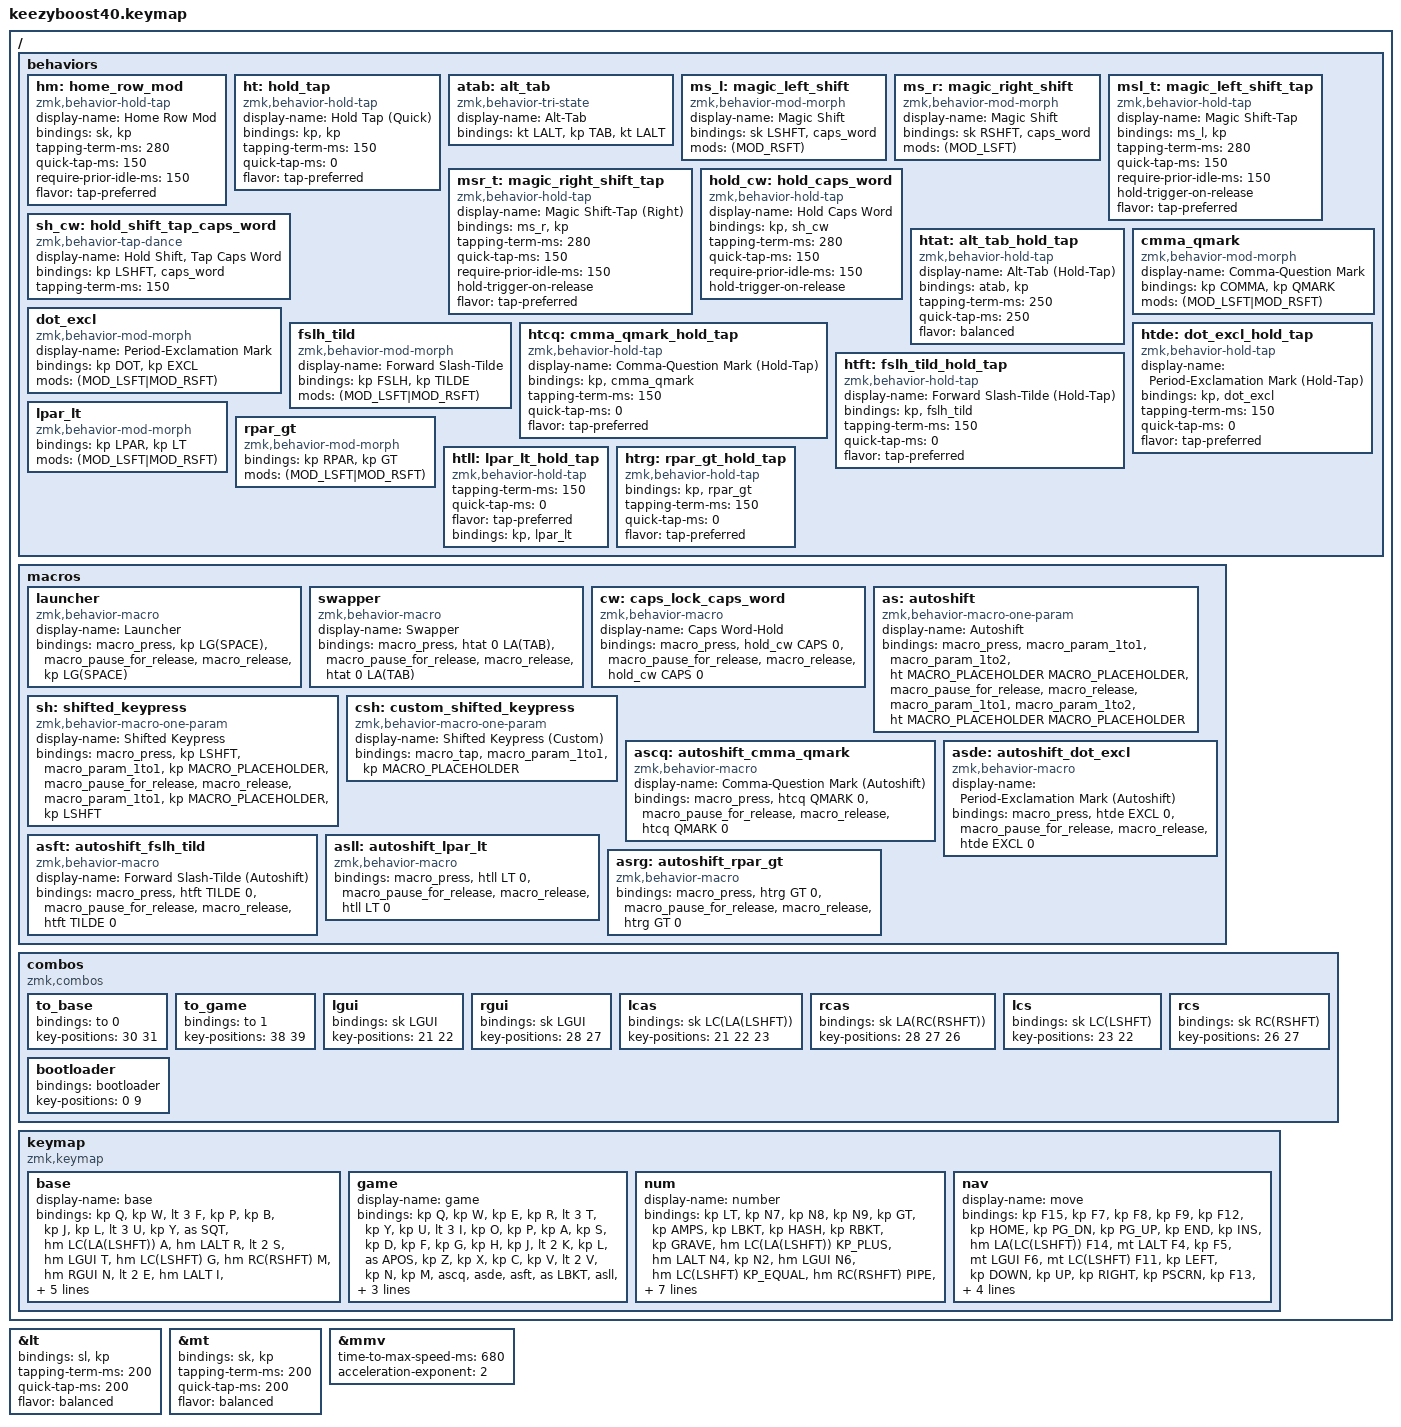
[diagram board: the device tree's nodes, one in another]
// dt-formatter: multilineListCommaStyle="leading"

#include <behaviors/none.dtsi>
#include <behaviors/transparent.dtsi>
#include <dt-bindings/zmk/mouse.h>
#include <behaviors.dtsi>
#include <dt-bindings/zmk/keys.h>

&lt {
    bindings = <&sl>, <&kp>;

    tapping-term-ms = <200>;
    quick-tap-ms = <200>;
    flavor = "balanced";
};

&mt {
    bindings = <&sk>, <&kp>;

    tapping-term-ms = <200>;
    quick-tap-ms = <200>;
    flavor = "balanced";
};

&mmv {
    time-to-max-speed-ms = <680>;
    acceleration-exponent = <2>;
};

/ {
    behaviors {
        hm: home_row_mod {
            display-name = "Home Row Mod";
            compatible = "zmk,behavior-hold-tap";
            #binding-cells = <2>;
            bindings = <&sk>, <&kp>;

            tapping-term-ms = <280>;
            quick-tap-ms = <150>;
            require-prior-idle-ms = <150>;
            flavor = "tap-preferred";
        };

        // Quick hold tap, i.e. for auto-shift

        ht: hold_tap {
            display-name = "Hold Tap (Quick)";
            compatible = "zmk,behavior-hold-tap";
            #binding-cells = <2>;
            bindings = <&kp>, <&kp>;

            tapping-term-ms = <150>;
            quick-tap-ms = <0>;
            flavor = "tap-preferred";
        };

        atab: alt_tab {
            display-name = "Alt-Tab";
            compatible = "zmk,behavior-tri-state";
            #binding-cells = <0>;
            bindings = <&kt LALT>, <&kp TAB>, <&kt LALT>;
        };

        // Unmodded: Left Shift | With Shift: Caps Word.

        ms_l: magic_left_shift {
            display-name = "Magic Shift";
            compatible = "zmk,behavior-mod-morph";
            #binding-cells = <0>;
            bindings = <&sk LSHFT>, <&caps_word>;

            mods = <(MOD_RSFT)>;
        };

        // Unmodded: Right Shift | With Shift: Caps Word.

        ms_r: magic_right_shift {
            display-name = "Magic Shift";
            compatible = "zmk,behavior-mod-morph";
            #binding-cells = <0>;
            bindings = <&sk RSHFT>, <&caps_word>;

            mods = <(MOD_LSFT)>;
        };

        // Hold: &ms_l | Tap: &kp

        msl_t: magic_left_shift_tap {
            display-name = "Magic Shift-Tap";
            compatible = "zmk,behavior-hold-tap";
            #binding-cells = <2>;
            bindings = <&ms_l>, <&kp>;

            tapping-term-ms = <280>;
            quick-tap-ms = <150>;
            require-prior-idle-ms = <150>;
            hold-trigger-on-release;
            flavor = "tap-preferred";
        };

        // Hold: &ms_r | Tap: &kp

        msr_t: magic_right_shift_tap {
            display-name = "Magic Shift-Tap (Right)";
            compatible = "zmk,behavior-hold-tap";
            #binding-cells = <2>;
            bindings = <&ms_r>, <&kp>;

            tapping-term-ms = <280>;
            quick-tap-ms = <150>;
            require-prior-idle-ms = <150>;
            hold-trigger-on-release;
            flavor = "tap-preferred";
        };

        hold_cw: hold_caps_word {
            display-name = "Hold Caps Word";
            compatible = "zmk,behavior-hold-tap";
            #binding-cells = <2>;
            bindings = <&kp>, <&sh_cw>;

            tapping-term-ms = <280>;
            quick-tap-ms = <150>;
            require-prior-idle-ms = <150>;
            hold-trigger-on-release;
        };

        sh_cw: hold_shift_tap_caps_word {
            display-name = "Hold Shift, Tap Caps Word";
            compatible = "zmk,behavior-tap-dance";
            #binding-cells = <0>;
            bindings = <&kp LSHFT>, <&caps_word>;

            tapping-term-ms = <150>;
        };

        htat: alt_tab_hold_tap {
            display-name = "Alt-Tab (Hold-Tap)";
            compatible = "zmk,behavior-hold-tap";
            #binding-cells = <2>;
            bindings = <&atab>, <&kp>;

            tapping-term-ms = <250>;
            quick-tap-ms = <250>;
            flavor = "balanced";
        };

        cmma_qmark: cmma_qmark {
            display-name = "Comma-Question Mark";
            compatible = "zmk,behavior-mod-morph";
            #binding-cells = <0>;
            bindings = <&kp COMMA>, <&kp QMARK>;

            mods = <(MOD_LSFT|MOD_RSFT)>;
        };

        dot_excl: dot_excl {
            display-name = "Period-Exclamation Mark";
            compatible = "zmk,behavior-mod-morph";
            #binding-cells = <0>;
            bindings = <&kp DOT>, <&kp EXCL>;

            mods = <(MOD_LSFT|MOD_RSFT)>;
        };

        fslh_tild: fslh_tild {
            display-name = "Forward Slash-Tilde";
            compatible = "zmk,behavior-mod-morph";
            #binding-cells = <0>;
            bindings = <&kp FSLH>, <&kp TILDE>;

            mods = <(MOD_LSFT|MOD_RSFT)>;
        };

        htcq: cmma_qmark_hold_tap {
            display-name = "Comma-Question Mark (Hold-Tap)";
            compatible = "zmk,behavior-hold-tap";
            #binding-cells = <2>;
            bindings = <&kp>, <&cmma_qmark>;

            tapping-term-ms = <150>;
            quick-tap-ms = <0>;
            flavor = "tap-preferred";
        };

        htde: dot_excl_hold_tap {
            display-name = "Period-Exclamation Mark (Hold-Tap)";
            compatible = "zmk,behavior-hold-tap";
            #binding-cells = <2>;
            bindings = <&kp>, <&dot_excl>;

            tapping-term-ms = <150>;
            quick-tap-ms = <0>;
            flavor = "tap-preferred";
        };

        htft: fslh_tild_hold_tap {
            display-name = "Forward Slash-Tilde (Hold-Tap)";
            compatible = "zmk,behavior-hold-tap";
            #binding-cells = <2>;
            bindings = <&kp>, <&fslh_tild>;

            tapping-term-ms = <150>;
            quick-tap-ms = <0>;
            flavor = "tap-preferred";
        };

        lpar_lt: lpar_lt {
            compatible = "zmk,behavior-mod-morph";
            bindings = <&kp LPAR>, <&kp LT>;

            #binding-cells = <0>;
            mods = <(MOD_LSFT|MOD_RSFT)>;
        };

        rpar_gt: rpar_gt {
            compatible = "zmk,behavior-mod-morph";
            bindings = <&kp RPAR>, <&kp GT>;

            #binding-cells = <0>;
            mods = <(MOD_LSFT|MOD_RSFT)>;
        };

        htll: lpar_lt_hold_tap {
            compatible = "zmk,behavior-hold-tap";
            #binding-cells = <2>;
            tapping-term-ms = <150>;
            quick-tap-ms = <0>;
            flavor = "tap-preferred";
            bindings = <&kp>, <&lpar_lt>;
        };

        htrg: rpar_gt_hold_tap {
            compatible = "zmk,behavior-hold-tap";
            bindings = <&kp>, <&rpar_gt>;

            #binding-cells = <2>;
            tapping-term-ms = <150>;
            quick-tap-ms = <0>;
            flavor = "tap-preferred";
        };
    };

    macros {
        launcher: launcher {
            display-name = "Launcher";
            compatible = "zmk,behavior-macro";
            #binding-cells = <0>;
            bindings
                = <&macro_press>
                , <&kp LG(SPACE)>
                , <&macro_pause_for_release>
                , <&macro_release>
                , <&kp LG(SPACE)>
                ;
        };

        swapper: swapper {
            display-name = "Swapper";
            compatible = "zmk,behavior-macro";
            #binding-cells = <0>;
            bindings
                = <&macro_press>
                , <&htat 0 LA(TAB)>
                , <&macro_pause_for_release>
                , <&macro_release>
                , <&htat 0 LA(TAB)>
                ;
        };

        /**
         * Swap windows
         * Windows/Linux: Grave-Tab
         * MacOS: Ctrl-Tab (Cmd-Tab if CMD_SWAP)
         */
        /**
         * Swap applications
         * Windows/Linux: Alt-Tab
         * MacOS: Cmd-Tab
         */
        // Hold: Caps Lock; Tap: Caps Word

        cw: caps_lock_caps_word {
            display-name = "Caps Word-Hold";
            compatible = "zmk,behavior-macro";
            #binding-cells = <0>;
            bindings
                = <&macro_press>
                , <&hold_cw CAPS 0>
                , <&macro_pause_for_release>
                , <&macro_release>
                , <&hold_cw CAPS 0>
                ;
        };

        as: autoshift {
            display-name = "Autoshift";
            compatible = "zmk,behavior-macro-one-param";
            #binding-cells = <1>;
            bindings
                = <&macro_press>
                , <&macro_param_1to1 &macro_param_1to2 &ht MACRO_PLACEHOLDER MACRO_PLACEHOLDER>
                , <&macro_pause_for_release>
                , <&macro_release>
                , <&macro_param_1to1 &macro_param_1to2 &ht MACRO_PLACEHOLDER MACRO_PLACEHOLDER>
                ;
        };

        sh: shifted_keypress {
            display-name = "Shifted Keypress";
            compatible = "zmk,behavior-macro-one-param";
            #binding-cells = <1>;
            bindings
                = <&macro_press>
                , <&kp LSHFT &macro_param_1to1 &kp MACRO_PLACEHOLDER>
                , <&macro_pause_for_release>
                , <&macro_release>
                , <&macro_param_1to1 &kp MACRO_PLACEHOLDER &kp LSHFT>
                ;
        };

        csh: custom_shifted_keypress {
            display-name = "Shifted Keypress (Custom)";
            compatible = "zmk,behavior-macro-one-param";
            #binding-cells = <1>;
            bindings = <&macro_tap>, <&macro_param_1to1 &kp MACRO_PLACEHOLDER>;
        };

        ascq: autoshift_cmma_qmark {
            display-name = "Comma-Question Mark (Autoshift)";
            compatible = "zmk,behavior-macro";
            #binding-cells = <0>;
            bindings
                = <&macro_press>
                , <&htcq QMARK 0>
                , <&macro_pause_for_release>
                , <&macro_release>
                , <&htcq QMARK 0>
                ;
        };

        asde: autoshift_dot_excl {
            display-name = "Period-Exclamation Mark (Autoshift)";
            compatible = "zmk,behavior-macro";
            #binding-cells = <0>;
            bindings
                = <&macro_press>
                , <&htde EXCL 0>
                , <&macro_pause_for_release>
                , <&macro_release>
                , <&htde EXCL 0>
                ;
        };

        asft: autoshift_fslh_tild {
            display-name = "Forward Slash-Tilde (Autoshift)";
            compatible = "zmk,behavior-macro";
            #binding-cells = <0>;
            bindings
                = <&macro_press>
                , <&htft TILDE 0>
                , <&macro_pause_for_release>
                , <&macro_release>
                , <&htft TILDE 0>
                ;
        };

        asll: autoshift_lpar_lt {
            compatible = "zmk,behavior-macro";
            #binding-cells = <0>;
            bindings
                = <&macro_press>
                , <&htll LT 0>
                , <&macro_pause_for_release>
                , <&macro_release>
                , <&htll LT 0>
                ;
        };

        asrg: autoshift_rpar_gt {
            compatible = "zmk,behavior-macro";
            #binding-cells = <0>;
            bindings
                = <&macro_press>
                , <&htrg GT 0>
                , <&macro_pause_for_release>
                , <&macro_release>
                , <&htrg GT 0>
                ;
        };
    };

    combos {
        compatible = "zmk,combos";

        to_base {
            bindings = <&to 0>;
            key-positions = <30 31>; // QWF
        };

        to_game {
            bindings = <&to 1>;
            key-positions = <38 39>; // WFP
        };

        lgui {
            bindings = <&sk LGUI>;
            key-positions = <21 22>; // RST
        };

        rgui {
            bindings = <&sk LGUI>;
            key-positions = <28 27>;  // NEI
        };

        lcas {
            bindings = <&sk LC(LA(LSHFT))>;
            key-positions = <21 22 23>;
        };

        rcas {
            bindings = <&sk LA(RC(RSHFT))>;
            key-positions = <28 27 26>;
        };

        lcs {
            bindings = <&sk LC(LSHFT)>;
            key-positions = <23 22>;
        };

        rcs {
            bindings = <&sk RC(RSHFT)>;
            key-positions = <26 27>;
        };

        bootloader {
            bindings = <&bootloader>;
            key-positions = <0 9>;
        };
    };

    keymap {
        compatible = "zmk,keymap";

        base {
            display-name = "base";

            // ┏━━━━━━━┳━━━━━━━┳━━━━━━━┳━━━━━━━┳━━━━━━━┳━━━━━━━┳━━━━━━━┳━━━━━━━┳━━━━━━━┳━━━━━━━┓
            // ┃   Q   ┃   W   ┃   F   ┃   P   ┃   B   ┃   J   ┃   L   ┃   U   ┃   Y   ┃   '   ┃
            // ┃       ┃       ┃ (nav) ┃       ┃       ┃       ┃       ┃ (nav) ┃       ┃       ┃
            // ┣━━━━━━━╋━━━━━━━╋━━━━━━━╋━━━━━━━╋━━━━━━━┫━━━━━━━╋━━━━━━━╋━━━━━━━╋━━━━━━━╋━━━━━━━┫
            // ┃   A   ┃   R   ┃   S   ┃   T   ┃   G   ┃   M   ┃   N   ┃   E   ┃   I   ┃   O   ┃
            // ┃ (^-⇧) ┃ (ALT) ┃ (num) ┃ (GUI) ┃       ┃       ┃ (GUI) ┃ (num) ┃ (ALT) ┃ (^-⇧) ┃
            // ┣━━━━━━━╋━━━━━━━╋━━━━━━━╋━━━━━━━╋━━━━━━━┫━━━━━━━╋━━━━━━━╋━━━━━━━╋━━━━━━━╋━━━━━━━┫
            // ┃   Z   ┃   X   ┃   C   ┃   D   ┃   V   ┃   K   ┃   H   ┃   ,   ┃   .   ┃   /   ┃
            // ╋━━━━━━━╋━━━━━━━╋━━━━━━━╋━━━━━━━╋━━━━━━━╋━━━━━━━╋━━━━━━━╋━━━━━━━╋━━━━━━━╋━━━━━━━┫
            // ┃       ┃       ┃  ESC  ┃ SPACE ┃  TAB  ┃ ENTER ┃ BSPC  ┃  DEL  ┃       ┃       ┃
            // ┃       ┃       ┃       ┃ (CTL) ┃ (SFT) ┃ (SFT) ┃ (CTL) ┃       ┃       ┃       ┃
            // ┗━━━━━━━┻━━━━━━━┻━━━━━━━┻━━━━━━━┻━━━━━━━┻━━━━━━━┻━━━━━━━┻━━━━━━━┻━━━━━━━┻━━━━━━━┛

            bindings = <
&kp Q  &kp W  &lt 3 F  &kp P  &kp B  &kp J  &kp L  &lt 3 U  &kp Y  &as SQT  &hm LC(LA(LSHFT)) A  &hm LALT R  &lt 2 S  &hm LGUI T  &hm LC(LSHFT) G  &hm RC(RSHFT) M  &hm RGUI N  &lt 2 E  &hm LALT I  &hm LA(RC(RSHFT)) O  &kp Z  &kp X  &kp C  &kp D  &kp V  &kp K  &kp H  &ascq  &asde  &asft  &as LBKT  &asll  &mt LALT ESC  &mt LCTRL SPACE  &mt LSHFT TAB  &mt RSHFT RET  &mt RCTRL BSPC  &mt LALT DEL  &asrg  &as RBKT
            >;
        };

        game {
            display-name = "game";

            // ┏━━━━━━━┳━━━━━━━┳━━━━━━━┳━━━━━━━┳━━━━━━━┳━━━━━━━┳━━━━━━━┳━━━━━━━┳━━━━━━━┳━━━━━━━┓
            // ┃   Q   ┃   W   ┃   F   ┃   P   ┃   B   ┃       ┃       ┃       ┃       ┃       ┃
            // ┣━━━━━━━╋━━━━━━━╋━━━━━━━╋━━━━━━━╋━━━━━━━┫━━━━━━━╋━━━━━━━╋━━━━━━━╋━━━━━━━╋━━━━━━━┫
            // ┃   A   ┃   R   ┃   S   ┃   T   ┃   G   ┃       ┃       ┃       ┃       ┃       ┃
            // ┣━━━━━━━╋━━━━━━━╋━━━━━━━╋━━━━━━━╋━━━━━━━┫━━━━━━━╋━━━━━━━╋━━━━━━━╋━━━━━━━╋━━━━━━━┫
            // ┃   Z   ┃   X   ┃   C   ┃   D   ┃   V   ┃       ┃       ┃       ┃       ┃       ┃
            // ╋━━━━━━━╋━━━━━━━╋━━━━━━━╋━━━━━━━╋━━━━━━━╋━━━━━━━╋━━━━━━━╋━━━━━━━╋━━━━━━━╋━━━━━━━┫
            // ┃  num  ┃  fun  ┃  ESC  ┃ SPACE ┃  TAB  ┃       ┃       ┃       ┃       ┃       ┃
            // ┃       ┃       ┃ (ALT) ┃ (CTL) ┃ (SFT) ┃       ┃       ┃       ┃       ┃       ┃
            // ┗━━━━━━━┻━━━━━━━┻━━━━━━━┻━━━━━━━┻━━━━━━━┻━━━━━━━┻━━━━━━━┻━━━━━━━┻━━━━━━━┻━━━━━━━┛

            bindings = <
&kp Q  &kp W  &kp E  &kp R  &lt 3 T  &kp Y  &kp U  &lt 3 I  &kp O  &kp P  &kp A  &kp S  &kp D  &kp F  &kp G  &kp H  &kp J  &lt 2 K  &kp L  &as APOS  &kp Z  &kp X  &kp C  &kp V  &lt 2 V  &kp N  &kp M  &ascq  &asde  &asft  &as LBKT  &asll  &mt LALT ESC  &mt LCTRL SPACE  &mt LSHFT TAB  &mt RSHFT RET  &mt RCTRL BSPC  &mt LALT DEL  &asrg  &as RBRC
            >;
        };

        num {
            display-name = "number";

            // ┏━━━━━━━┳━━━━━━━┳━━━━━━━┳━━━━━━━┳━━━━━━━┳━━━━━━━┳━━━━━━━┳━━━━━━━┳━━━━━━━┳━━━━━━━┓
            // ┃   [   ┃   7   ┃   8   ┃   9   ┃   ]   ┃   {   ┃   &   ┃   #   ┃   @   ┃   }   ┃
            // ┣━━━━━━━╋━━━━━━━╋━━━━━━━╋━━━━━━━╋━━━━━━━┫━━━━━━━╋━━━━━━━╋━━━━━━━╋━━━━━━━╋━━━━━━━┫
            // ┃   +   ┃   4   ┃   5   ┃   6   ┃   =   ┃   ^   ┃   _   ┃   `   ┃   $   ┃   :   ┃
            // ┃       ┃ (ALT) ┃ (num) ┃ (GUI) ┃       ┃       ┃ (GUI) ┃ (num) ┃ (ALT) ┃       ┃
            // ┣━━━━━━━╋━━━━━━━╋━━━━━━━╋━━━━━━━╋━━━━━━━┫━━━━━━━╋━━━━━━━╋━━━━━━━╋━━━━━━━╋━━━━━━━┫
            // ┃   *   ┃   1   ┃   2   ┃   3   ┃   \   ┃   |   ┃   %   ┃   <   ┃   >   ┃   ;   ┃
            // ╋━━━━━━━╋━━━━━━━╋━━━━━━━╋━━━━━━━╋━━━━━━━╋━━━━━━━╋━━━━━━━╋━━━━━━━╋━━━━━━━╋━━━━━━━┫
            // ┃       ┃       ┃   5   ┃   0   ┃   -   ┃   (   ┃   )   ┃   `   ┃       ┃       ┃
            // ┃       ┃       ┃       ┃ (CTL) ┃ (SFT) ┃ (SFT) ┃ (CTL) ┃       ┃       ┃       ┃
            // ┗━━━━━━━┻━━━━━━━┻━━━━━━━┻━━━━━━━┻━━━━━━━┻━━━━━━━┻━━━━━━━┻━━━━━━━┻━━━━━━━┻━━━━━━━┛

            bindings = <
&kp LT  &kp N7  &kp N8  &kp N9  &kp GT  &kp AMPS  &kp LBKT  &kp HASH  &kp RBKT  &kp GRAVE  &hm LC(LA(LSHFT)) KP_PLUS  &hm LALT N4  &kp N2  &hm LGUI N6  &hm LC(LSHFT) KP_EQUAL  &hm RC(RSHFT) PIPE  &hm RGUI LPAR  &kp GRAVE  &hm LALT RPAR  &ht RC(LA(RSHFT)) COLON  &kp KP_MULTIPLY  &kp N1  &kp N2  &kp N3  &kp KP_DIVIDE  &as BSLH  &kp LBRC  &kp PRCNT  &kp RBRC  &kp SEMI  &trans  &trans  &mt LALT KP_DOT  &mt LCTRL N0  &mt LSHFT KP_MINUS  &mt RSHFT UNDER  &mt RCTRL CARET  &mt LALT DLLR  &trans  &trans
            >;
        };

        nav {
            display-name = "move";

            // ┏━━━━━━━┳━━━━━━━┳━━━━━━━┳━━━━━━━┳━━━━━━━┳━━━━━━━┳━━━━━━━┳━━━━━━━┳━━━━━━━┳━━━━━━━┓
            // ┃  ^-Q  ┃  ^-W  ┃  ^-F  ┃  ^-P  ┃  ^-B  ┃  HOME ┃ PG DN ┃ PG UP ┃  END  ┃ mouse ┃
            // ┃       ┃       ┃ (nav) ┃       ┃       ┃       ┃       ┃ (nav) ┃       ┃       ┃
            // ┣━━━━━━━╋━━━━━━━╋━━━━━━━╋━━━━━━━╋━━━━━━━┣━━━━━━━╋━━━━━━━╋━━━━━━━╋━━━━━━━╋━━━━━━━┫
            // ┃  ^-A  ┃  ^-R  ┃  ^-S  ┃  ^-T  ┃  ^-G  ┃  LEFT ┃ DOWN  ┃  UP   ┃ RIGHT ┃ PSCRN ┃
            // ┣━━━━━━━╋━━━━━━━╋━━━━━━━╋━━━━━━━╋━━━━━━━╋━━━━━━━╋━━━━━━━╋━━━━━━━╋━━━━━━━╋━━━━━━━┫
            // ┃  ^-Z  ┃  ^-X  ┃  ^-C  ┃  ^-V  ┃ ^-⇧-Z ┃  ^-K  ┃  ^-H  ┃  ^-,  ┃  ^-.  ┃  ^-/  ┃
            // ┣━━━━━━━╋━━━━━━━╋━━━━━━━╋━━━━━━━╋━━━━━━━╋━━━━━━━╋━━━━━━━╋━━━━━━━╋━━━━━━━╋━━━━━━━┫
            // ┃       ┃       ┃  ESC  ┃ SPACE ┃  TAB  ┃ ENTER ┃  BSPC ┃  DEL  ┃       ┃       ┃
            // ┃       ┃       ┃       ┃ (CTL) ┃ (SFT) ┃ (SFT) ┃ (CTL) ┃       ┃       ┃       ┃
            // ┗━━━━━━━┻━━━━━━━┻━━━━━━━┻━━━━━━━┻━━━━━━━┻━━━━━━━┻━━━━━━━┻━━━━━━━┻━━━━━━━┻━━━━━━━┛

            bindings = <
&kp F15  &kp F7  &kp F8  &kp F9  &kp F12  &kp HOME  &kp PG_DN  &kp PG_UP  &kp END  &kp INS  &hm LA(LC(LSHFT)) F14  &mt LALT F4  &kp F5  &mt LGUI F6  &mt LC(LSHFT) F11  &kp LEFT  &kp DOWN  &kp UP  &kp RIGHT  &kp PSCRN  &kp F13  &kp F1  &kp F2  &kp F3  &kp F10  &sk RSHFT  &sk RCTRL  &sk LALT  &sk RGUI  &none  &trans  &trans  &trans  &trans  &trans  &trans  &trans  &trans  &trans  &trans
            >;
        };
    };
};
